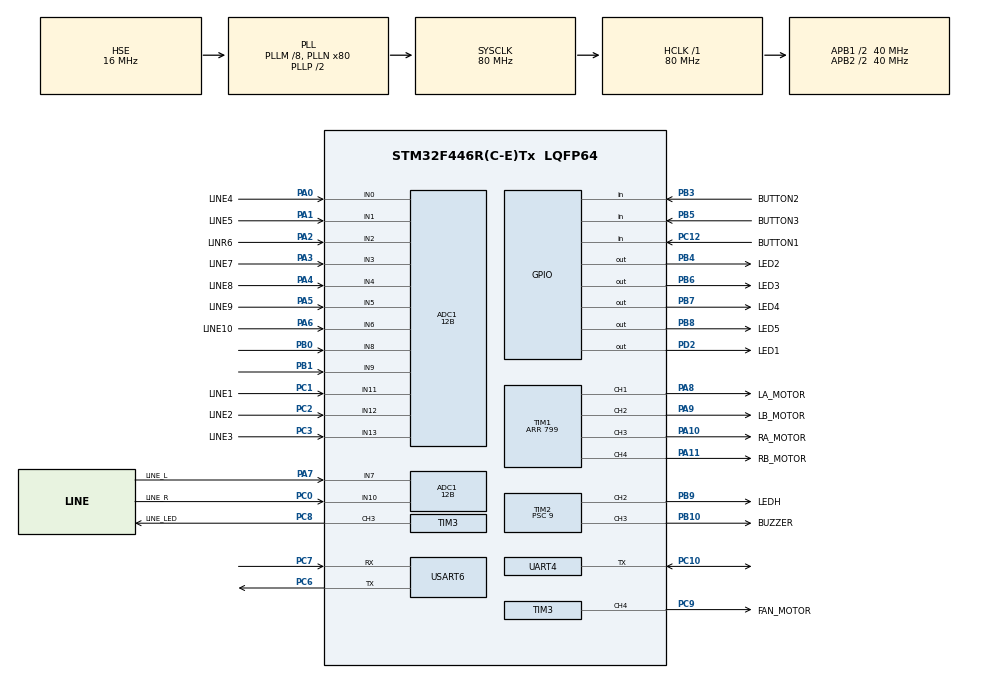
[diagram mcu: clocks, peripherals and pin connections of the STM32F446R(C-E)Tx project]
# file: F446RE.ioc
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ADC1.Channel-0\#ChannelRegularConversion=ADC_CHANNEL_8
ADC1.Channel-1\#ChannelRegularConversion=ADC_CHANNEL_9
ADC1.Channel-10\#ChannelRegularConversion=ADC_CHANNEL_3
ADC1.Channel-11\#ChannelRegularConversion=ADC_CHANNEL_4
ADC1.Channel-12\#ChannelRegularConversion=ADC_CHANNEL_5
ADC1.Channel-13\#ChannelRegularConversion=ADC_CHANNEL_6
ADC1.Channel-2\#ChannelRegularConversion=ADC_CHANNEL_10
ADC1.Channel-3\#ChannelRegularConversion=ADC_CHANNEL_7
ADC1.Channel-4\#ChannelRegularConversion=ADC_CHANNEL_11
ADC1.Channel-5\#ChannelRegularConversion=ADC_CHANNEL_12
ADC1.Channel-6\#ChannelRegularConversion=ADC_CHANNEL_13
ADC1.Channel-7\#ChannelRegularConversion=ADC_CHANNEL_0
ADC1.Channel-8\#ChannelRegularConversion=ADC_CHANNEL_1
ADC1.Channel-9\#ChannelRegularConversion=ADC_CHANNEL_2
ADC1.ClockPrescaler=ADC_CLOCK_SYNC_PCLK_DIV2
ADC1.ContinuousConvMode=ENABLE
ADC1.DMAContinuousRequests=ENABLE
ADC1.DiscontinuousConvMode=DISABLE
ADC1.EOCSelection=ADC_EOC_SINGLE_CONV
ADC1.InjNumberOfConversion=0
ADC1.NbrOfConversion=14
ADC1.NbrOfConversionFlag=1
ADC1.Rank-1\#ChannelRegularConversion=2
ADC1.Rank-10\#ChannelRegularConversion=11
ADC1.Rank-11\#ChannelRegularConversion=12
ADC1.Rank-12\#ChannelRegularConversion=13
ADC1.Rank-13\#ChannelRegularConversion=14
ADC1.Rank-2\#ChannelRegularConversion=3
ADC1.Rank-3\#ChannelRegularConversion=4
ADC1.Rank-4\#ChannelRegularConversion=5
ADC1.Rank-5\#ChannelRegularConversion=6
ADC1.Rank-6\#ChannelRegularConversion=7
ADC1.Rank-7\#ChannelRegularConversion=8
ADC1.Rank-8\#ChannelRegularConversion=9
ADC1.Rank-9\#ChannelRegularConversion=10
ADC1.Resolution=ADC_RESOLUTION_12B
ADC1.SamplingTime-0\#ChannelRegularConversion=ADC_SAMPLETIME_112CYCLES
ADC1.SamplingTime-1\#ChannelRegularConversion=ADC_SAMPLETIME_112CYCLES
ADC1.SamplingTime-10\#ChannelRegularConversion=ADC_SAMPLETIME_480CYCLES
ADC1.SamplingTime-11\#ChannelRegularConversion=ADC_SAMPLETIME_480CYCLES
ADC1.SamplingTime-12\#ChannelRegularConversion=ADC_SAMPLETIME_480CYCLES
ADC1.SamplingTime-13\#ChannelRegularConversion=ADC_SAMPLETIME_480CYCLES
ADC1.SamplingTime-2\#ChannelRegularConversion=ADC_SAMPLETIME_112CYCLES
ADC1.SamplingTime-3\#ChannelRegularConversion=ADC_SAMPLETIME_112CYCLES
ADC1.SamplingTime-4\#ChannelRegularConversion=ADC_SAMPLETIME_480CYCLES
ADC1.SamplingTime-5\#ChannelRegularConversion=ADC_SAMPLETIME_480CYCLES
ADC1.SamplingTime-6\#ChannelRegularConversion=ADC_SAMPLETIME_480CYCLES
ADC1.SamplingTime-7\#ChannelRegularConversion=ADC_SAMPLETIME_480CYCLES
ADC1.SamplingTime-8\#ChannelRegularConversion=ADC_SAMPLETIME_480CYCLES
ADC1.SamplingTime-9\#ChannelRegularConversion=ADC_SAMPLETIME_480CYCLES
ADC1.master=1
Dma.ADC1.0.Direction=DMA_PERIPH_TO_MEMORY
Dma.ADC1.0.FIFOMode=DMA_FIFOMODE_DISABLE
Dma.ADC1.0.Instance=DMA2_Stream0
Dma.ADC1.0.MemDataAlignment=DMA_MDATAALIGN_HALFWORD
Dma.ADC1.0.MemInc=DMA_MINC_ENABLE
Dma.ADC1.0.Mode=DMA_CIRCULAR
Dma.ADC1.0.PeriphDataAlignment=DMA_PDATAALIGN_HALFWORD
Dma.ADC1.0.PeriphInc=DMA_PINC_DISABLE
Dma.ADC1.0.Priority=DMA_PRIORITY_LOW
Dma.Request0=ADC1
Dma.Request1=USART6_RX
Dma.Request2=USART6_TX
Dma.USART6_RX.1.Direction=DMA_PERIPH_TO_MEMORY
Dma.USART6_RX.1.FIFOMode=DMA_FIFOMODE_DISABLE
Dma.USART6_RX.1.Instance=DMA2_Stream1
Dma.USART6_RX.1.MemDataAlignment=DMA_MDATAALIGN_BYTE
Dma.USART6_RX.1.MemInc=DMA_MINC_ENABLE
Dma.USART6_RX.1.Mode=DMA_CIRCULAR
Dma.USART6_RX.1.PeriphDataAlignment=DMA_PDATAALIGN_BYTE
Dma.USART6_RX.1.PeriphInc=DMA_PINC_DISABLE
Dma.USART6_RX.1.Priority=DMA_PRIORITY_LOW
Dma.USART6_TX.2.Direction=DMA_MEMORY_TO_PERIPH
Dma.USART6_TX.2.FIFOMode=DMA_FIFOMODE_DISABLE
Dma.USART6_TX.2.Instance=DMA2_Stream6
Dma.USART6_TX.2.MemDataAlignment=DMA_MDATAALIGN_BYTE
Dma.USART6_TX.2.MemInc=DMA_MINC_ENABLE
Dma.USART6_TX.2.Mode=DMA_NORMAL
Dma.USART6_TX.2.PeriphDataAlignment=DMA_PDATAALIGN_BYTE
Dma.USART6_TX.2.PeriphInc=DMA_PINC_DISABLE
Dma.USART6_TX.2.Priority=DMA_PRIORITY_LOW
Mcu.Family=STM32F4
Mcu.Name=STM32F446R(C-E)Tx
Mcu.Package=LQFP64
NVIC.DMA2_Stream0_IRQn=true\:0\:0\:false\:false\:true\:false\:true\:true
NVIC.DMA2_Stream1_IRQn=true\:0\:0\:false\:false\:true\:false\:true\:true
NVIC.DMA2_Stream6_IRQn=true\:0\:0\:false\:false\:true\:false\:true\:true
NVIC.PriorityGroup=NVIC_PRIORITYGROUP_4
NVIC.TIM1_TRG_COM_TIM11_IRQn=true\:0\:0\:false\:false\:true\:true\:true\:true
NVIC.TIM1_UP_TIM10_IRQn=true\:0\:0\:false\:false\:true\:true\:true\:true
NVIC.USART6_IRQn=true\:0\:0\:false\:false\:true\:true\:true\:true
PA0-WKUP.GPIO_Label=LINE4
PA0-WKUP.GPIO_Mode=GPIO_MODE_ANALOG
PA0-WKUP.GPIO_PuPd=GPIO_NOPULL
PA0-WKUP.Signal=ADCx_IN0
PA1.GPIO_Label=LINE5
PA1.GPIO_Mode=GPIO_MODE_ANALOG
PA1.GPIO_PuPd=GPIO_NOPULL
PA1.Signal=ADCx_IN1
PA10.GPIO_Label=RA_MOTOR
PA10.Signal=S_TIM1_CH3
PA11.GPIO_Label=RB_MOTOR
PA11.Signal=S_TIM1_CH4
PA13.Signal=SYS_JTMS-SWDIO
PA14.Signal=SYS_JTCK-SWCLK
PA2.GPIO_Label=LINR6
PA2.GPIO_Mode=GPIO_MODE_ANALOG
PA2.GPIO_PuPd=GPIO_NOPULL
PA2.Signal=ADCx_IN2
PA3.GPIO_Label=LINE7
PA3.GPIO_Mode=GPIO_MODE_ANALOG
PA3.GPIO_PuPd=GPIO_NOPULL
PA3.Signal=ADCx_IN3
PA4.GPIO_Label=LINE8
PA4.GPIO_Mode=GPIO_MODE_ANALOG
PA4.GPIO_PuPd=GPIO_NOPULL
PA4.Signal=ADCx_IN4
PA5.GPIO_Label=LINE9
PA5.GPIO_Mode=GPIO_MODE_ANALOG
PA5.GPIO_PuPd=GPIO_NOPULL
PA5.Signal=ADCx_IN5
PA6.GPIO_Label=LINE10
PA6.GPIO_Mode=GPIO_MODE_ANALOG
PA6.GPIO_PuPd=GPIO_NOPULL
PA6.Signal=ADCx_IN6
PA7.GPIO_Label=LINE_L
PA7.GPIO_Mode=GPIO_MODE_ANALOG
PA7.GPIO_PuPd=GPIO_NOPULL
PA7.Signal=ADCx_IN7
PA8.GPIO_Label=LA_MOTOR
PA8.Signal=S_TIM1_CH1
PA9.GPIO_Label=LB_MOTOR
PA9.Signal=S_TIM1_CH2
PB0.Signal=ADCx_IN8
PB1.Signal=ADCx_IN9
PB10.GPIO_Label=BUZZER
PB10.Signal=S_TIM2_CH3
PB3.GPIO_Label=BUTTON2
PB3.Signal=GPIO_Input
PB4.GPIO_Label=LED2
PB4.Signal=GPIO_Output
PB5.GPIO_Label=BUTTON3
PB5.Signal=GPIO_Input
PB6.GPIO_Label=LED3
PB6.Signal=GPIO_Output
PB7.GPIO_Label=LED4
PB7.Signal=GPIO_Output
PB8.GPIO_Label=LED5
PB8.Signal=GPIO_Output
PB9.GPIO_Label=LEDH
PB9.Signal=S_TIM2_CH2
PC0.GPIO_Label=LINE_R
PC0.GPIO_Mode=GPIO_MODE_ANALOG
PC0.GPIO_PuPd=GPIO_NOPULL
PC0.Signal=ADCx_IN10
PC1.GPIO_Label=LINE1
PC1.GPIO_Mode=GPIO_MODE_ANALOG
PC1.GPIO_PuPd=GPIO_NOPULL
PC1.Signal=ADCx_IN11
PC10.Mode=Half_duplex(single_wire_mode)
PC10.Signal=UART4_TX
PC12.GPIO_Label=BUTTON1
PC12.Signal=GPIO_Input
PC2.GPIO_Label=LINE2
PC2.GPIO_Mode=GPIO_MODE_ANALOG
PC2.GPIO_PuPd=GPIO_NOPULL
PC2.Signal=ADCx_IN12
PC3.GPIO_Label=LINE3
PC3.GPIO_Mode=GPIO_MODE_ANALOG
PC3.GPIO_PuPd=GPIO_NOPULL
PC3.Signal=ADCx_IN13
PC6.Mode=Asynchronous
PC6.Signal=USART6_TX
PC7.Mode=Asynchronous
PC7.Signal=USART6_RX
PC8.GPIO_Label=LINE_LED
PC8.Signal=S_TIM3_CH3
PC9.GPIO_Label=FAN_MOTOR
PC9.Signal=S_TIM3_CH4
PD2.GPIO_Label=LED1
PD2.Signal=GPIO_Output
PH0-OSC_IN.Mode=HSE-External-Oscillator
PH0-OSC_IN.Signal=RCC_OSC_IN
PH1-OSC_OUT.Mode=HSE-External-Oscillator
PH1-OSC_OUT.Signal=RCC_OSC_OUT
ProjectManager.HeapSize=0x200
ProjectManager.StackSize=0x400
ProjectManager.TargetToolchain=Makefile
RCC.AHBFreq_Value=80000000
RCC.APB1CLKDivider=RCC_HCLK_DIV2
RCC.APB1Freq_Value=40000000
RCC.APB1TimFreq_Value=80000000
RCC.APB2CLKDivider=RCC_HCLK_DIV2
RCC.APB2Freq_Value=40000000
RCC.APB2TimFreq_Value=80000000
RCC.CortexFreq_Value=80000000
RCC.HCLKFreq_Value=80000000
RCC.HSE_VALUE=16000000
RCC.PLLM=8
RCC.PLLN=80
RCC.PLLSourceVirtual=RCC_PLLSOURCE_HSE
RCC.SYSCLKFreq_VALUE=80000000
RCC.SYSCLKSource=RCC_SYSCLKSOURCE_PLLCLK
RCC.USBFreq_Value=80000000
RCC.VCOOutputFreq_Value=160000000
SH.ADCx_IN0.0=ADC1_IN0,IN0
SH.ADCx_IN1.0=ADC1_IN1,IN1
SH.ADCx_IN10.0=ADC1_IN10,IN10
SH.ADCx_IN11.0=ADC1_IN11,IN11
SH.ADCx_IN12.0=ADC1_IN12,IN12
SH.ADCx_IN13.0=ADC1_IN13,IN13
SH.ADCx_IN2.0=ADC1_IN2,IN2
SH.ADCx_IN3.0=ADC1_IN3,IN3
SH.ADCx_IN4.0=ADC1_IN4,IN4
SH.ADCx_IN5.0=ADC1_IN5,IN5
SH.ADCx_IN6.0=ADC1_IN6,IN6
SH.ADCx_IN7.0=ADC1_IN7,IN7
SH.ADCx_IN8.0=ADC1_IN8,IN8
SH.ADCx_IN9.0=ADC1_IN9,IN9
SH.S_TIM1_CH1.0=TIM1_CH1,PWM Generation1 CH1
SH.S_TIM1_CH2.0=TIM1_CH2,PWM Generation2 CH2
SH.S_TIM1_CH3.0=TIM1_CH3,PWM Generation3 CH3
SH.S_TIM1_CH4.0=TIM1_CH4,PWM Generation4 CH4
SH.S_TIM2_CH2.0=TIM2_CH2,PWM Generation2 CH2
SH.S_TIM2_CH3.0=TIM2_CH3,PWM Generation3 CH3
SH.S_TIM3_CH3.0=TIM3_CH3,PWM Generation3 CH3
SH.S_TIM3_CH4.0=TIM3_CH4,PWM Generation4 CH4
TIM1.Channel-PWM\ Generation1\ CH1=TIM_CHANNEL_1
TIM1.Channel-PWM\ Generation2\ CH2=TIM_CHANNEL_2
TIM1.Channel-PWM\ Generation3\ CH3=TIM_CHANNEL_3
TIM1.Channel-PWM\ Generation4\ CH4=TIM_CHANNEL_4
TIM1.Period=799
TIM10.Period=9
TIM10.Prescaler=7999
TIM2.Channel-PWM\ Generation2\ CH2=TIM_CHANNEL_2
TIM2.Channel-PWM\ Generation3\ CH3=TIM_CHANNEL_3
TIM2.Period=9999
TIM2.Prescaler=9
TIM3.Channel-PWM\ Generation3\ CH3=TIM_CHANNEL_3
TIM3.Channel-PWM\ Generation4\ CH4=TIM_CHANNEL_4
TIM3.Period=799
UART4.VirtualMode=Asynchronous
USART6.VirtualMode=VM_ASYNC
VP_TIM10_VS_ClockSourceINT.Mode=Enable_Timer
VP_TIM1_VS_ClockSourceINT.Mode=Internal
VP_TIM2_VS_ClockSourceINT.Mode=Internal
VP_TIM3_VS_ClockSourceINT.Mode=Internal
board=custom

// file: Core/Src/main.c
/* USER CODE BEGIN Header */
/**
 ******************************************************************************
 * @file           : main.c
 * @brief          : Main program body
 ******************************************************************************
 * @attention
 *
 * Copyright (c) 2024 STMicroelectronics.
 * All rights reserved.
 *
 * This software is licensed under terms that can be found in the LICENSE file
 * in the root directory of this software component.
 * If no LICENSE file comes with this software, it is provided AS-IS.
 *
 ******************************************************************************
 */
/* USER CODE END Header */
#include "main.h"
#include "adc.h"
#include "dma.h"
#include "tim.h"
#include "usart.h"
#include "gpio.h"

/* USER CODE BEGIN Includes */
#include <stdio.h>
/* USER CODE END Includes */

void SystemClock_Config(void);

/* USER CODE BEGIN 0 */
int _write(int file, char *ptr, int len) {
      HAL_UART_Transmit(&huart4, (uint8_t *)ptr, len, 10);
      return len;
}

void HAL_TIM_PeriodElapsedCallback(TIM_HandleTypeDef *htim) {
      if (htim == &htim10) {
            TimInterrupt1khz();
      }
}
/* USER CODE END 0 */

int main(void)
{

  /* USER CODE BEGIN 1 */
      setbuf(stdout, NULL);
  /* USER CODE END 1 */

  /* MCU Configuration--------------------------------------------------------*/

  /* Reset of all peripherals, Initializes the Flash interface and the Systick. */
  HAL_Init();

  /* Configure the system clock */
  SystemClock_Config();

  /* Initialize all configured peripherals */
  MX_GPIO_Init();
  MX_DMA_Init();
  MX_ADC1_Init();
  MX_UART4_Init();
  MX_USART6_UART_Init();
  MX_TIM1_Init();
  MX_TIM3_Init();
  MX_TIM2_Init();
  MX_TIM10_Init();
  /* USER CODE BEGIN 2 */
      setup();
      HAL_TIM_Base_Start_IT(&htim10);
  /* USER CODE END 2 */

  /* Infinite loop */
  /* USER CODE BEGIN WHILE */
      main_app();
      while (1) {
    /* USER CODE END WHILE */

      }
}

void SystemClock_Config(void)
{
  RCC_OscInitTypeDef RCC_OscInitStruct = {0};
  RCC_ClkInitTypeDef RCC_ClkInitStruct = {0};

  /** Configure the main internal regulator output voltage
  */
  __HAL_RCC_PWR_CLK_ENABLE();
  __HAL_PWR_VOLTAGESCALING_CONFIG(PWR_REGULATOR_VOLTAGE_SCALE3);

  /** Initializes the RCC Oscillators according to the specified parameters
  * in the RCC_OscInitTypeDef structure.
  */
  RCC_OscInitStruct.OscillatorType = RCC_OSCILLATORTYPE_HSE;
  RCC_OscInitStruct.HSEState = RCC_HSE_ON;
  RCC_OscInitStruct.PLL.PLLState = RCC_PLL_ON;
  RCC_OscInitStruct.PLL.PLLSource = RCC_PLLSOURCE_HSE;
  RCC_OscInitStruct.PLL.PLLM = 8;
  RCC_OscInitStruct.PLL.PLLN = 80;
  RCC_OscInitStruct.PLL.PLLP = RCC_PLLP_DIV2;
  RCC_OscInitStruct.PLL.PLLQ = 2;
  RCC_OscInitStruct.PLL.PLLR = 2;
  if (HAL_RCC_OscConfig(&RCC_OscInitStruct) != HAL_OK)
  {
    Error_Handler();
  }

  /** Initializes the CPU, AHB and APB buses clocks
  */
  RCC_ClkInitStruct.ClockType = RCC_CLOCKTYPE_HCLK|RCC_CLOCKTYPE_SYSCLK
                              |RCC_CLOCKTYPE_PCLK1|RCC_CLOCKTYPE_PCLK2;
  RCC_ClkInitStruct.SYSCLKSource = RCC_SYSCLKSOURCE_PLLCLK;
  RCC_ClkInitStruct.AHBCLKDivider = RCC_SYSCLK_DIV1;
  RCC_ClkInitStruct.APB1CLKDivider = RCC_HCLK_DIV2;
  RCC_ClkInitStruct.APB2CLKDivider = RCC_HCLK_DIV2;

  if (HAL_RCC_ClockConfig(&RCC_ClkInitStruct, FLASH_LATENCY_2) != HAL_OK)
  {
    Error_Handler();
  }
}

void Error_Handler(void)
{
      __disable_irq();
      while (1) {
      }
}
